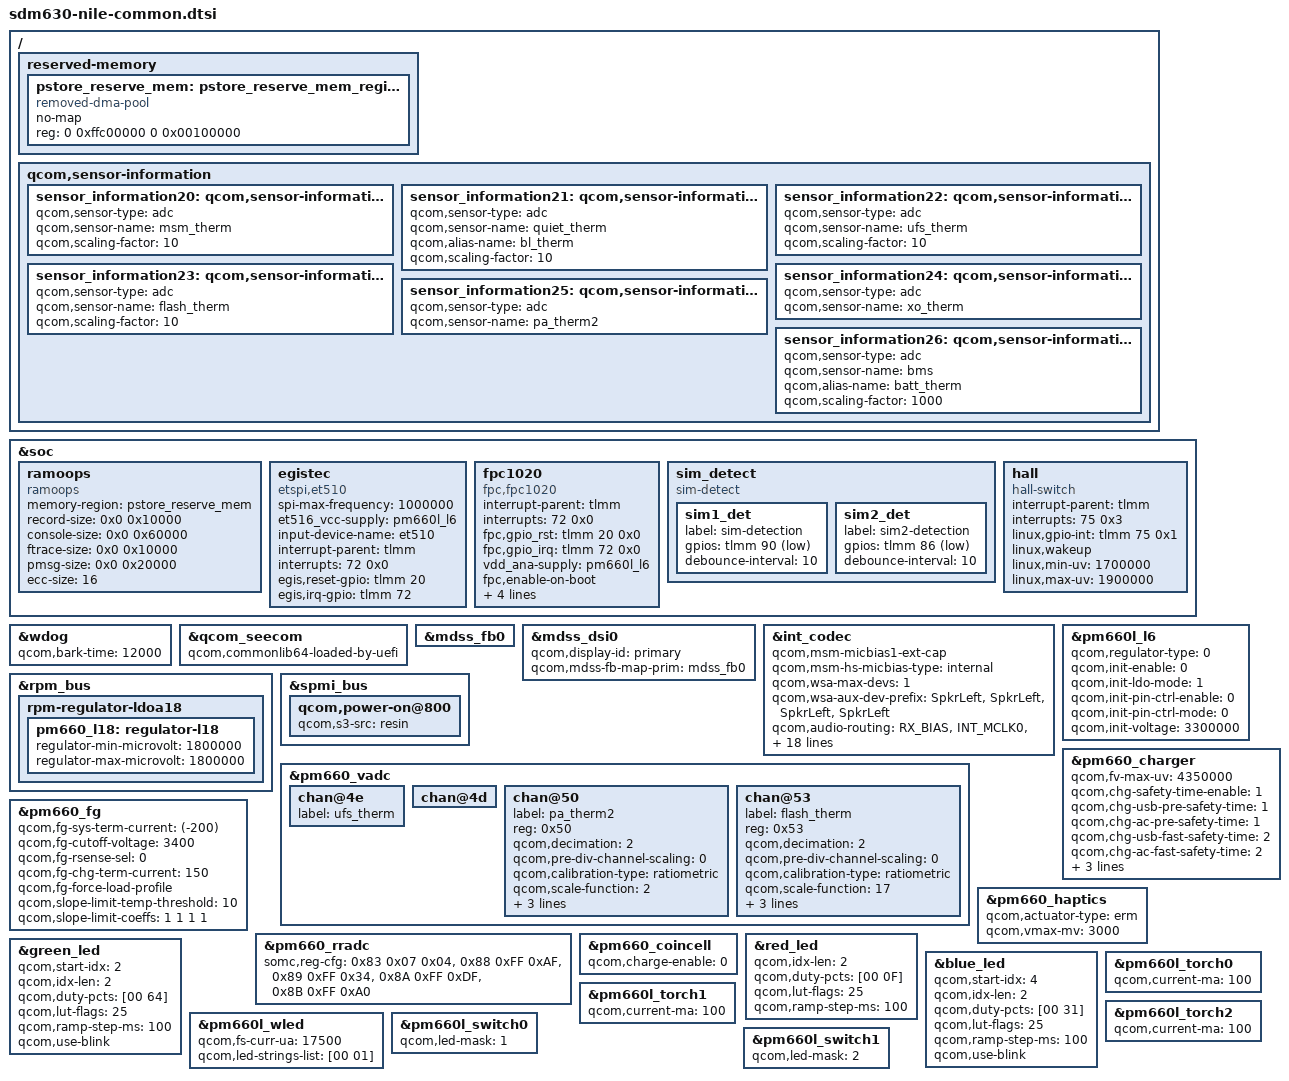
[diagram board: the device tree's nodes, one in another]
/* Copyright (c) 2016-2017, The Linux Foundation. All rights reserved.
 *
 * This program is free software; you can redistribute it and/or modify
 * it under the terms of the GNU General Public License version 2 and
 * only version 2 as published by the Free Software Foundation.
 *
 * This program is distributed in the hope that it will be useful,
 * but WITHOUT ANY WARRANTY; without even the implied warranty of
 * MERCHANTABILITY or FITNESS FOR A PARTICULAR PURPOSE.  See the
 * GNU General Public License for more details.
 */

#include "sdm630-nile_pinctrl.dtsi"

/ {
	reserved-memory {
		pstore_reserve_mem: pstore_reserve_mem_region_region@ffc00000 {
			compatible = "removed-dma-pool";
			no-map;
			reg = <0 0xffc00000 0 0x00100000>;
		};
	};

	qcom,sensor-information {
		sensor_information20: qcom,sensor-information-20 { /* msm_therm */
			qcom,sensor-type =  "adc";
			qcom,sensor-name = "msm_therm";
			qcom,scaling-factor = <10>;
		};
		sensor_information21: qcom,sensor-information-21 { /* quiet_therm */
			qcom,sensor-type =  "adc";
			qcom,sensor-name = "quiet_therm";
			qcom,alias-name = "bl_therm";
			qcom,scaling-factor = <10>;
		};
		sensor_information22: qcom,sensor-information-22 { /* ufs_therm */
			qcom,sensor-type = "adc";
			qcom,sensor-name = "ufs_therm";
			qcom,scaling-factor = <10>;
		};
		sensor_information23: qcom,sensor-information-23 { /* flash_therm */
			qcom,sensor-type = "adc";
			qcom,sensor-name = "flash_therm";
			qcom,scaling-factor = <10>;
		};
		sensor_information24: qcom,sensor-information-24 { /* xo_therm */
			qcom,sensor-type = "adc";
			qcom,sensor-name = "xo_therm";
		};
		sensor_information25: qcom,sensor-information-25 { /* pa_therm2 */
			qcom,sensor-type = "adc";
			qcom,sensor-name = "pa_therm2";
		};
		sensor_information26: qcom,sensor-information-26 { /* bms */
			qcom,sensor-type = "adc";
			qcom,sensor-name = "bms";
			qcom,alias-name = "batt_therm";
			qcom,scaling-factor = <1000>;
		};
	};
};

&soc {
	ramoops {
		compatible = "ramoops";
		memory-region = <&pstore_reserve_mem>;
		record-size = <0x0 0x10000>;
		console-size = <0x0 0x60000>;
		ftrace-size = <0x0 0x10000>;
		pmsg-size = <0x0 0x20000>;
		ecc-size = <16>;
	};

	egistec {
		compatible = "etspi,et510";
		spi-max-frequency = <1000000>;
		et516_vcc-supply = <&pm660l_l6>;
		input-device-name = "et510";
		interrupt-parent = <&tlmm>;
		interrupts = <72 0x0>;
		egis,reset-gpio    = <&tlmm 20 0>;
		egis,irq-gpio      = <&tlmm 72 0>;
	};

	fpc1020 {
		status = "ok";
		compatible = "fpc,fpc1020";
		interrupt-parent = <&tlmm>;
		interrupts = <72 0x0>;
	fpc,gpio_rst    = <&tlmm 20 0x0>;
	fpc,gpio_irq    = <&tlmm 72 0x0>;
		vdd_ana-supply = <&pm660l_l6>;
	fpc,enable-on-boot;
	fpc,enable-wakeup;

	pinctrl-names = "fpc1020_reset_reset",
		"fpc1020_reset_active",
		"fpc1020_irq_active";

	pinctrl-0 = <&msm_gpio_20>;
	pinctrl-1 = <&msm_gpio_20_output_high>;
	pinctrl-2 = <&msm_gpio_72>;
	};

	sim_detect {
		compatible = "sim-detect";

		sim1_det {
			label = "sim-detection";
			gpios = <&tlmm 90 0x1>;
			debounce-interval = <10>;
		};

		sim2_det {
			label = "sim2-detection";
			gpios = <&tlmm 86 0x1>;
			debounce-interval = <10>;
		};
	};

	hall {
		compatible = "hall-switch";
		interrupt-parent = <&tlmm>;
		interrupts = <75 0x3>;
		//vddio-supply = <&pm660l_l14>;
		linux,gpio-int = <&tlmm 75 0x1>;
		linux,wakeup;
		linux,min-uv = <1700000>;
		linux,max-uv = <1900000>;
	};
};

&wdog {
	qcom,bark-time = <12000>;
};

&qcom_seecom {
	qcom,commonlib64-loaded-by-uefi;
};

&mdss_fb0 {
	/delete-node/ qcom,cont-splash-memory;
};

&mdss_dsi0 {
	qcom,display-id = "primary";
	qcom,mdss-fb-map-prim = <&mdss_fb0>;
};

&int_codec {
	/delete-property/ qcom,msm-micbias2-ext-cap;
	qcom,msm-micbias1-ext-cap;
	qcom,msm-hs-micbias-type = "internal";

	qcom,wsa-max-devs = <1>;
	qcom,wsa-aux-dev-prefix = "SpkrLeft", "SpkrLeft",
				  "SpkrLeft", "SpkrLeft";

	qcom,audio-routing =
		"RX_BIAS", "INT_MCLK0",
		"SPK_RX_BIAS", "INT_MCLK0",
		"INT_LDO_H", "INT_MCLK0",
		"RX_I2S_CLK", "INT_MCLK0",
		"TX_I2S_CLK", "INT_MCLK0",
		"MIC BIAS External", "Handset Mic",
		"MIC BIAS Internal2", "Headset Mic",
		"MIC BIAS External", "Secondary Mic",
		"AMIC1", "MIC BIAS External",
		"AMIC2", "MIC BIAS Internal2",
		"AMIC3", "MIC BIAS External",
		"DMIC1", "MIC BIAS External",
		"MIC BIAS External", "Digital Mic1",
		"DMIC2", "MIC BIAS External",
		"MIC BIAS External", "Digital Mic2",
		"DMIC3", "MIC BIAS External",
		"MIC BIAS External", "Digital Mic3",
		"DMIC4", "MIC BIAS External",
		"MIC BIAS External", "Digital Mic4",
		"SpkrLeft IN", "SPK1 OUT",
		"SpkrRight IN", "SPK2 OUT",
		"PDM_IN_RX1", "PDM_OUT_RX1",
		"PDM_IN_RX2", "PDM_OUT_RX2",
		"PDM_IN_RX3", "PDM_OUT_RX3",
		"ADC1_IN", "ADC1_OUT",
		"ADC2_IN", "ADC2_OUT",
		"ADC3_IN", "ADC3_OUT";
};

&rpm_bus {
	rpm-regulator-ldoa18 {
		status = "okay";
		pm660_l18: regulator-l18 {
			regulator-min-microvolt = <1800000>;
			regulator-max-microvolt = <1800000>;
			status = "okay";
		};
	};
};

&pm660l_l6 {
	qcom,regulator-type = <0>;  /* LDO */
	qcom,init-enable = <0>;
	qcom,init-ldo-mode = <1>;
	qcom,init-pin-ctrl-enable = <0>;
	qcom,init-pin-ctrl-mode = <0>;
	qcom,init-voltage = <3300000>;
};

/* PM660 */
&spmi_bus {
	qcom,power-on@800 {
		qcom,s3-src = "resin";
	};
};

&pm660_vadc {
	chan@4e {
		label = "ufs_therm";
	};

	chan@4d {
		//checkme msm_therm stock is qcom,scale-function = <17>;
	};

	chan@50 {
		label = "pa_therm2";
		reg = <0x50>;
		qcom,decimation = <2>;
		qcom,pre-div-channel-scaling = <0>;
		qcom,calibration-type = "ratiometric";
		qcom,scale-function = <2>;
		qcom,hw-settle-time = <2>;
		qcom,fast-avg-setup = <0>;
		qcom,vadc-thermal-node;
	};

	chan@53 {
		label = "flash_therm";
		reg = <0x53>;
		qcom,decimation = <2>;
		qcom,pre-div-channel-scaling = <0>;
		qcom,calibration-type = "ratiometric";
		qcom,scale-function = <17>;
		qcom,hw-settle-time = <2>;
		qcom,fast-avg-setup = <0>;
		qcom,vadc-thermal-node;
	};
};

&pm660_charger {
	qcom,fv-max-uv = <4350000>;
	qcom,chg-safety-time-enable = <1>;
	qcom,chg-usb-pre-safety-time = <1>;
	qcom,chg-ac-pre-safety-time = <1>;
	qcom,chg-usb-fast-safety-time = <2>;
	qcom,chg-ac-fast-safety-time = <2>;
	qcom,float-option = <2>;
	qcom,thermal-mitigation = <2400000 1000000 500000 200000>;
};

&pm660_fg {
	qcom,fg-sys-term-current = <(-200)>;
	qcom,fg-cutoff-voltage = <3400>;
	qcom,fg-rsense-sel = <0>;
	qcom,fg-chg-term-current = <150>;
	qcom,fg-force-load-profile;
	qcom,slope-limit-temp-threshold = <10>;
	qcom,slope-limit-coeffs = <1 1 1 1>;
};

&pm660_rradc {
	somc,reg-cfg =
	      /* addr mask value */
	      <0x83 0x07 0x04>, /* FG_ADC_RR_AUX_THERM_CFG */
	      <0x88 0xFF 0xAF>, /* FG_ADC_RR_AUX_THERM_C1 */
	      <0x89 0xFF 0x34>, /* FG_ADC_RR_AUX_THERM_C2 */
	      <0x8A 0xFF 0xDF>, /* FG_ADC_RR_AUX_THERM_C3 */
	      <0x8B 0xFF 0xA0>; /* FG_ADC_RR_AUX_THERM_HALF_RANGE */
};

&pm660_haptics {
	qcom,actuator-type = "erm";
	qcom,vmax-mv = <3000>;
};

&pm660_coincell {
	qcom,charge-enable = <0>;
};

/* PM660L */
&red_led {
	qcom,idx-len = <2>;
	qcom,duty-pcts = [00 0F];
	qcom,lut-flags = <25>;
	qcom,ramp-step-ms = <100>;
};

&green_led {
	qcom,start-idx = <2>;
	qcom,idx-len = <2>;
	qcom,duty-pcts = [00 64];
	qcom,lut-flags = <25>;
	qcom,ramp-step-ms = <100>;
	qcom,use-blink;
};

&blue_led {
	qcom,start-idx = <4>;
	qcom,idx-len = <2>;
	qcom,duty-pcts = [00 31];
	qcom,lut-flags = <25>;
	qcom,ramp-step-ms = <100>;
	qcom,use-blink;
};

&pm660l_wled {
	qcom,fs-curr-ua = <17500>;
	qcom,led-strings-list = [00 01];
};

&pm660l_torch0 {
	qcom,current-ma = <100>;
};

&pm660l_torch1 {
	qcom,current-ma = <100>;
};

&pm660l_torch2 {
	qcom,current-ma = <100>;
};

&pm660l_switch0 {
	qcom,led-mask = <1>;
};

&pm660l_switch1 {
	qcom,led-mask = <2>;
};

